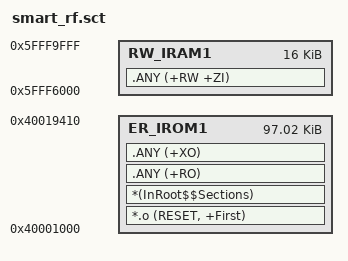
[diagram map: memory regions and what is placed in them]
; *************************************************************
; *** Scatter-Loading Description File generated by uVision ***
; *************************************************************

LR_IROM1 0x40001000 0x00018411  {    ; load region size_region
  ER_IROM1 0x40001000 0x00018411  {  ; load address = execution address
   *.o (RESET, +First)
   *(InRoot$$Sections)
   .ANY (+RO)
   .ANY (+XO)
  }
  RW_IRAM1 0x5FFF6000 0x00004000  {  ; RW data
   .ANY (+RW +ZI)
  }
}

